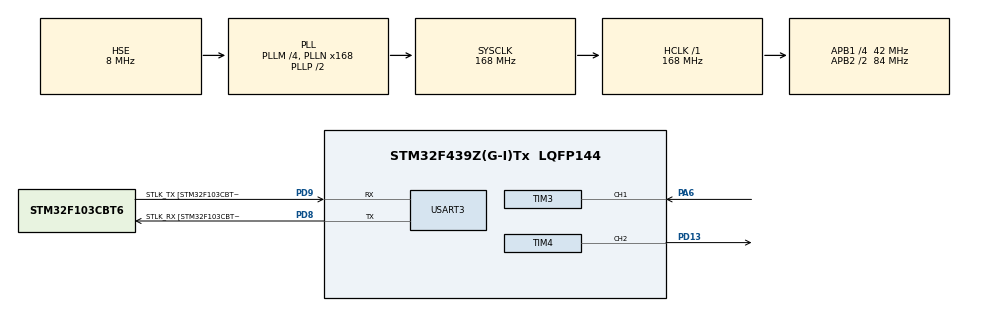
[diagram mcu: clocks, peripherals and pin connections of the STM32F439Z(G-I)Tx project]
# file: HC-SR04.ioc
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Mcu.Family=STM32F4
Mcu.Name=STM32F439Z(G-I)Tx
Mcu.Package=LQFP144
NVIC.PriorityGroup=NVIC_PRIORITYGROUP_4
NVIC.TIM3_IRQn=true\:0\:0\:false\:false\:true\:true\:true\:true
PA6.Signal=S_TIM3_CH1
PC14/OSC32_IN.Mode=LSE-External-Oscillator
PC14/OSC32_IN.Signal=RCC_OSC32_IN
PC15/OSC32_OUT.Mode=LSE-External-Oscillator
PC15/OSC32_OUT.Signal=RCC_OSC32_OUT
PD13.Signal=S_TIM4_CH2
PD8.GPIO_Label=STLK_RX [STM32F103CBT6_PA3]
PD8.Mode=Asynchronous
PD8.Signal=USART3_TX
PD9.GPIO_Label=STLK_TX [STM32F103CBT6_PA2]
PD9.Mode=Asynchronous
PD9.Signal=USART3_RX
PH0/OSC_IN.GPIO_Label=MCO [STM32F103CBT6_PA8]
PH0/OSC_IN.Mode=HSE-External-Clock-Source
PH0/OSC_IN.Signal=RCC_OSC_IN
PH1/OSC_OUT.Mode=HSE-External-Clock-Source
PH1/OSC_OUT.Signal=RCC_OSC_OUT
ProjectManager.HeapSize=0x200
ProjectManager.StackSize=0x400
ProjectManager.TargetToolchain=STM32CubeIDE
RCC.48MHZClocksFreq_Value=48000000
RCC.AHBFreq_Value=168000000
RCC.APB1CLKDivider=RCC_HCLK_DIV4
RCC.APB1Freq_Value=42000000
RCC.APB1TimFreq_Value=84000000
RCC.APB2CLKDivider=RCC_HCLK_DIV2
RCC.APB2Freq_Value=84000000
RCC.APB2TimCLKDivider=2
RCC.APB2TimFreq_Value=168000000
RCC.CortexFreq_Value=168000000
RCC.HCLKFreq_Value=168000000
RCC.HSE_VALUE=8000000
RCC.HSI_VALUE=16000000
RCC.PLLM=4
RCC.PLLMUL=RCC_PLL_MUL9
RCC.PLLN=168
RCC.PLLQ=7
RCC.PLLSourceVirtual=RCC_PLLSOURCE_HSE
RCC.PRESCALERUSB=RCC_USBCLKSOURCE_PLL_DIV1_5
RCC.SYSCLKFreq_VALUE=168000000
RCC.SYSCLKSource=RCC_SYSCLKSOURCE_PLLCLK
RCC.SYSCLKSourceVirtual=RCC_SYSCLKSOURCE_PLLCLK
RCC.USBFreq_Value=48000000
RCC.VCOOutputFreq_Value=336000000
SH.S_TIM3_CH1.0=TIM3_CH1,Input_Capture1_from_TI1
SH.S_TIM4_CH2.0=TIM4_CH2,PWM Generation2 CH2
TIM3.Channel-Input_Capture1_from_TI1=TIM_CHANNEL_1
TIM3.Prescaler=83
TIM4.AutoReloadPreload=TIM_AUTORELOAD_PRELOAD_DISABLE
TIM4.Channel-PWM\ Generation2\ CH2=TIM_CHANNEL_2
TIM4.Period=49
TIM4.Prescaler=83
TIM4.Pulse-PWM\ Generation2\ CH2=10
USART3.VirtualMode=VM_ASYNC
VP_TIM4_VS_OPM.Mode=OPM_bit
board=NUCLEO-F439ZI

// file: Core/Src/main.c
/* USER CODE BEGIN Header */
/**
  ******************************************************************************
  * @file           : main.c
  * @brief          : Main program body
  ******************************************************************************
  * @attention
  *
  * Copyright (c) 2025 STMicroelectronics.
  * All rights reserved.
  *
  * This software is licensed under terms that can be found in the LICENSE file
  * in the root directory of this software component.
  * If no LICENSE file comes with this software, it is provided AS-IS.
  *
  ******************************************************************************
  */
/* USER CODE END Header */
#include "main.h"

/* USER CODE BEGIN Includes */
#include "ultrasonic_sensor_driver.h"
#include <stdio.h>
/* USER CODE END Includes */

TIM_HandleTypeDef htim3;
TIM_HandleTypeDef htim4;

UART_HandleTypeDef huart3;

void SystemClock_Config(void);
static void MX_GPIO_Init(void);
static void MX_TIM3_Init(void);
static void MX_TIM4_Init(void);
static void MX_USART3_UART_Init(void);

/* USER CODE BEGIN 0 */
extern UART_HandleTypeDef huart3;
int _write(int file, char *ptr, int len) {
    HAL_UART_Transmit(&huart3, (uint8_t*)ptr, len, HAL_MAX_DELAY);
    return len;
}

ultrasonic_Handle_t front_ultrasonic_sensor;
/* USER CODE END 0 */

int main(void)
{

  /* MCU Configuration--------------------------------------------------------*/

  /* Reset of all peripherals, Initializes the Flash interface and the Systick. */
  HAL_Init();

  /* Configure the system clock */
  SystemClock_Config();

  /* Initialize all configured peripherals */
  MX_GPIO_Init();
  MX_TIM3_Init();
  MX_TIM4_Init();
  MX_USART3_UART_Init();
  /* USER CODE BEGIN 2 */

  front_ultrasonic_sensor.htim_echo = &htim3;
  front_ultrasonic_sensor.echo_channel = TIM_CHANNEL_1;
  front_ultrasonic_sensor.htim_trig = &htim4;
  front_ultrasonic_sensor.trig_channel = TIM_CHANNEL_2;
  Ultrasonic_Sensor_Init(&front_ultrasonic_sensor);
  uint32_t last_trigger = 0;
  printf("Waiting for ultrasonic sensor.\n");
  /* USER CODE END 2 */

  /* Infinite loop */
  while (1)
  {
      uint32_t now = HAL_GetTick();

      // 1. Trigger every 60 ms
      if (now - last_trigger >= 60) {
          if (Ultrasonic_Trigger(&front_ultrasonic_sensor) == ULTRASONIC_OK) {
              last_trigger = now;
          }
      }

      // 2. Check for measurement completion CONTINUOUSLY
      if (Ultrasonic_IsReady(&front_ultrasonic_sensor)) {
          float distance = Ultrasonic_GetDistance(&front_ultrasonic_sensor);

          int i = (int)distance;
          int f = (int)((distance - i) * 100);

          printf("DISTANCE = %d.%02d cm\r\n", i, f);
      }
  }

}

void SystemClock_Config(void)
{
  RCC_OscInitTypeDef RCC_OscInitStruct = {0};
  RCC_ClkInitTypeDef RCC_ClkInitStruct = {0};

  /** Configure the main internal regulator output voltage
  */
  __HAL_RCC_PWR_CLK_ENABLE();
  __HAL_PWR_VOLTAGESCALING_CONFIG(PWR_REGULATOR_VOLTAGE_SCALE1);

  /** Initializes the RCC Oscillators according to the specified parameters
  * in the RCC_OscInitTypeDef structure.
  */
  RCC_OscInitStruct.OscillatorType = RCC_OSCILLATORTYPE_HSE;
  RCC_OscInitStruct.HSEState = RCC_HSE_BYPASS;
  RCC_OscInitStruct.PLL.PLLState = RCC_PLL_ON;
  RCC_OscInitStruct.PLL.PLLSource = RCC_PLLSOURCE_HSE;
  RCC_OscInitStruct.PLL.PLLM = 4;
  RCC_OscInitStruct.PLL.PLLN = 168;
  RCC_OscInitStruct.PLL.PLLP = RCC_PLLP_DIV2;
  RCC_OscInitStruct.PLL.PLLQ = 7;
  if (HAL_RCC_OscConfig(&RCC_OscInitStruct) != HAL_OK)
  {
    Error_Handler();
  }

  /** Initializes the CPU, AHB and APB buses clocks
  */
  RCC_ClkInitStruct.ClockType = RCC_CLOCKTYPE_HCLK|RCC_CLOCKTYPE_SYSCLK
                              |RCC_CLOCKTYPE_PCLK1|RCC_CLOCKTYPE_PCLK2;
  RCC_ClkInitStruct.SYSCLKSource = RCC_SYSCLKSOURCE_PLLCLK;
  RCC_ClkInitStruct.AHBCLKDivider = RCC_SYSCLK_DIV1;
  RCC_ClkInitStruct.APB1CLKDivider = RCC_HCLK_DIV4;
  RCC_ClkInitStruct.APB2CLKDivider = RCC_HCLK_DIV2;

  if (HAL_RCC_ClockConfig(&RCC_ClkInitStruct, FLASH_LATENCY_5) != HAL_OK)
  {
    Error_Handler();
  }
}

static void MX_TIM3_Init(void)
{

  TIM_MasterConfigTypeDef sMasterConfig = {0};
  TIM_IC_InitTypeDef sConfigIC = {0};

  htim3.Instance = TIM3;
  htim3.Init.Prescaler = 83;
  htim3.Init.CounterMode = TIM_COUNTERMODE_UP;
  htim3.Init.Period = 65535;
  htim3.Init.ClockDivision = TIM_CLOCKDIVISION_DIV1;
  htim3.Init.AutoReloadPreload = TIM_AUTORELOAD_PRELOAD_DISABLE;
  if (HAL_TIM_IC_Init(&htim3) != HAL_OK)
  {
    Error_Handler();
  }
  sMasterConfig.MasterOutputTrigger = TIM_TRGO_RESET;
  sMasterConfig.MasterSlaveMode = TIM_MASTERSLAVEMODE_DISABLE;
  if (HAL_TIMEx_MasterConfigSynchronization(&htim3, &sMasterConfig) != HAL_OK)
  {
    Error_Handler();
  }
  sConfigIC.ICPolarity = TIM_INPUTCHANNELPOLARITY_RISING;
  sConfigIC.ICSelection = TIM_ICSELECTION_DIRECTTI;
  sConfigIC.ICPrescaler = TIM_ICPSC_DIV1;
  sConfigIC.ICFilter = 0;
  if (HAL_TIM_IC_ConfigChannel(&htim3, &sConfigIC, TIM_CHANNEL_1) != HAL_OK)
  {
    Error_Handler();
  }

}

static void MX_TIM4_Init(void)
{

  TIM_MasterConfigTypeDef sMasterConfig = {0};
  TIM_OC_InitTypeDef sConfigOC = {0};

  htim4.Instance = TIM4;
  htim4.Init.Prescaler = 83;
  htim4.Init.CounterMode = TIM_COUNTERMODE_UP;
  htim4.Init.Period = 49;
  htim4.Init.ClockDivision = TIM_CLOCKDIVISION_DIV1;
  htim4.Init.AutoReloadPreload = TIM_AUTORELOAD_PRELOAD_DISABLE;
  if (HAL_TIM_PWM_Init(&htim4) != HAL_OK)
  {
    Error_Handler();
  }
  if (HAL_TIM_OnePulse_Init(&htim4, TIM_OPMODE_SINGLE) != HAL_OK)
  {
    Error_Handler();
  }
  sMasterConfig.MasterOutputTrigger = TIM_TRGO_RESET;
  sMasterConfig.MasterSlaveMode = TIM_MASTERSLAVEMODE_DISABLE;
  if (HAL_TIMEx_MasterConfigSynchronization(&htim4, &sMasterConfig) != HAL_OK)
  {
    Error_Handler();
  }
  sConfigOC.OCMode = TIM_OCMODE_PWM1;
  sConfigOC.Pulse = 10;
  sConfigOC.OCPolarity = TIM_OCPOLARITY_HIGH;
  sConfigOC.OCFastMode = TIM_OCFAST_DISABLE;
  if (HAL_TIM_PWM_ConfigChannel(&htim4, &sConfigOC, TIM_CHANNEL_2) != HAL_OK)
  {
    Error_Handler();
  }
  HAL_TIM_MspPostInit(&htim4);

}

static void MX_USART3_UART_Init(void)
{

  huart3.Instance = USART3;
  huart3.Init.BaudRate = 115200;
  huart3.Init.WordLength = UART_WORDLENGTH_8B;
  huart3.Init.StopBits = UART_STOPBITS_1;
  huart3.Init.Parity = UART_PARITY_NONE;
  huart3.Init.Mode = UART_MODE_TX_RX;
  huart3.Init.HwFlowCtl = UART_HWCONTROL_NONE;
  huart3.Init.OverSampling = UART_OVERSAMPLING_16;
  if (HAL_UART_Init(&huart3) != HAL_OK)
  {
    Error_Handler();
  }

}

static void MX_GPIO_Init(void)
{

  /* GPIO Ports Clock Enable */
  __HAL_RCC_GPIOC_CLK_ENABLE();
  __HAL_RCC_GPIOH_CLK_ENABLE();
  __HAL_RCC_GPIOA_CLK_ENABLE();
  __HAL_RCC_GPIOD_CLK_ENABLE();

}

void Error_Handler(void)
{
  __disable_irq();
  while (1)
  {
  }
}
